# fpga register map
File version: 1.0
Registers are 32-bit, read-write, reset 0x0 unless marked. A register's access mark holds for its fields unless they carry their own. Offsets are from the block's base; [hi:lo] are bit positions; {n}, {i} and the like mark numbered series; 'fields as' and 'values as' point back to an identical list; <NAME> marks a mode.

## steppers — 8-channel stepper motor step/dir pulse generator (2 banks of 4)
Base 0x90000D00
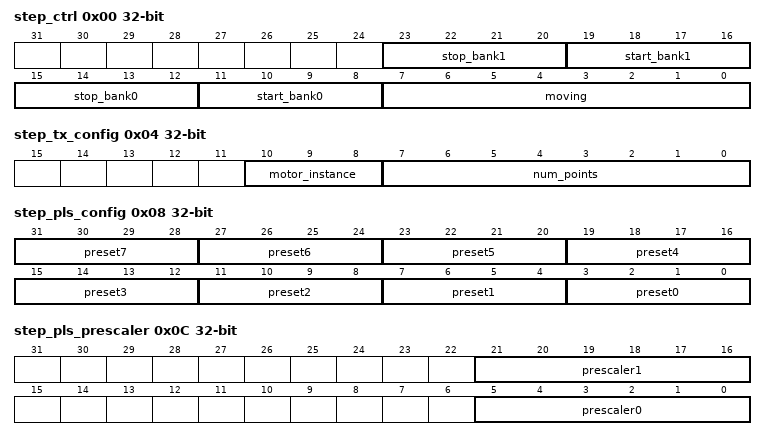
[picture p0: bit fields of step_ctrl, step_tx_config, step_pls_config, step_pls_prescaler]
0x00 step_ctrl — start/stop control - WRITE: start/stop strobes per motor (bank 0 = motors 0-3, bank 1 = motors 4-7); READ: per-motor moving status
  [23:20] stop_bank1 wo — stop strobe, bit N = motor (N+4) (bank 1, motors 4-7) - write-only, always reads as 0
  [19:16] start_bank1 wo — start strobe, bit N = motor (N+4) (bank 1, motors 4-7) - write-only, always reads as 0
  [15:12] stop_bank0 wo — stop strobe, bit N = motor N (bank 0, motors 0-3) - write-only, always reads as 0
  [11:8] start_bank0 wo — start strobe, bit N = motor N (bank 0, motors 0-3) - write-only, always reads as 0
  [7:0] moving ro — per-motor moving status (bit N = motor N is moving) - read-only, ignored on write
0x04 step_tx_config — segment table streaming configuration - selects which motor subsequent step_seg_ctst/step_seg_spdm writes and reads target, and rewinds both the write and read pointers to segment 0
  [10:8] motor_instance — which motor (0-7) subsequent step_seg_ctst/step_seg_spdm accesses target
  [7:0] num_points — number of segments about to be streamed (informational - clamped internally to the segment table's actual capacity)
0x08 step_pls_config — per-motor step pulse width preset (tick count - 1). Combined with that motor's bank prescaler in step_pls_prescaler: pulse width = (prescaler+1) * (preset+1) sys_clk cycles
  [4n+3:4n] preset{n} (n=0..7) — motor {n} pulse-width preset (tick count - 1)
0x0C step_pls_prescaler — per-bank step pulse width prescaler (sys_clk cycles per tick - 1). Bank 0 = motors 0-3 (low 16-bit half, bits[5:0]), bank 1 = motors 4-7 (high 16-bit half, bits[21:16]) - split this way so either field can widen, or other per-bank config bits can be added, without touching the other bank's half
  [21:16] prescaler1 — bank 1 (motors 4-7) prescaler (sys_clk cycles per tick - 1), high 16-bit half
  [5:0] prescaler0 — bank 0 (motors 0-3) prescaler (sys_clk cycles per tick - 1), low 16-bit half
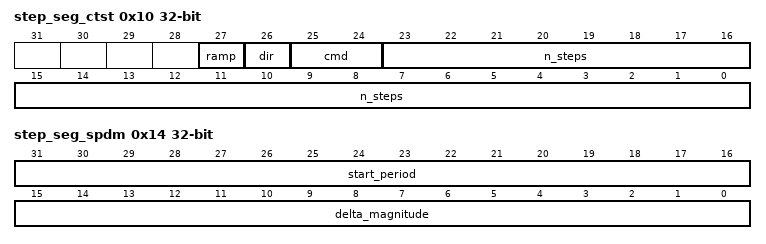
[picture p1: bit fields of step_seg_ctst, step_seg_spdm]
0x10 step_seg_ctst — segment table CTST word - command/direction/step-count for the segment addressed by step_tx_config's motor_instance and the current streaming pointer (advances on step_seg_spdm access, not this one)
  [27] ramp — whether this segment's period ramps up or down progresses
    0=UP (period decreases each step (accelerating)); 1=DOWN (period increases each step (decelerating))
  [26] dir — step direction for this segment
    0=NORMAL (forward/increasing position); 1=REVERSE (reverse/decreasing position)
  [25:24] cmd — segment command
    1=MOVE (move this segment then seamlessly continue into the next segment); 2=MOVE_HALT (move this segment then halt, requiring a fresh start strobe); 3=MOVE_HALT_WAIT (move this segment then halt, requiring a fresh start strobe (reserved alias of MOVE_HALT))
  [23:0] n_steps — number of steps in this segment
0x14 step_seg_spdm — segment table SPDM word - start period/delta magnitude for the segment addressed by step_tx_config's motor_instance and the current streaming pointer (advances the streaming pointer on access - write or read)
  [31:16] start_period — starting period for this segment, in stepper ticks
  [15:0] delta_magnitude — per-step period change magnitude, in stepper ticks
{0x20+4i} step_status_{i} ro (i=0..7) — motor {i} status
  [0] moving — 1 = motor is currently moving
{0x40+4i} step_pos_{i} ro (i=0..7) — motor {i} current absolute position, in steps (signed, two's complement)
  [31:0] position — current absolute position (signed, two's complement)

## timer_pwm — 4 independent 8-bit timers (source clock, 8-bit prescaler, 8-bit auto-reload) feeding 12 flexibly-mapped PWM output channels (PM1-4, OT1-8)
Base 0x90000E00
0x00 pwm_ctrl — master PWM output control - disabling forces every one of the 12 PWM pins LOW regardless of per-channel enable/polarity, and drives ot_en to its inactive (isolated) level
  [0] output_enable — 1 = PWM outputs active and ot_en drives OT1-8's isolation buffer enabled; 0 (reset default) = every PWM pin forced LOW and OT1-8 electrically isolated
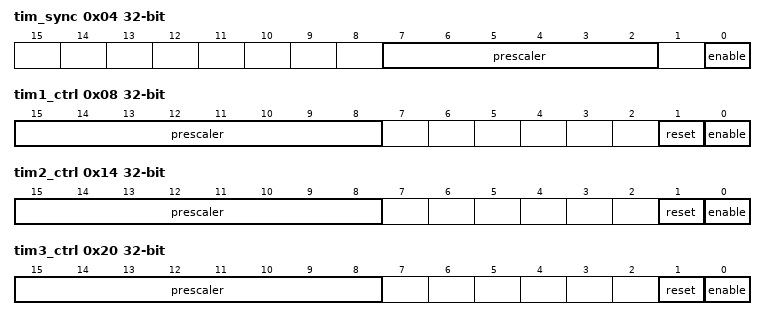
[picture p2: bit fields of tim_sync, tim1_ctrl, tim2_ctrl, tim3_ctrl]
0x04 tim_sync — global timer counting gate - lets every configured timer be started phase-aligned on the same sys_clk edge, plus a shared prescaler ahead of all 4 timers' own prescalers
  [7:2] prescaler — divide-1, shared by all 4 timers ahead of each timer's own timN_ctrl.prescaler: a timer only advances on a sys_clk cycle this shared stage ticks on, so the effective divide to one timer tick is (prescaler+1) * (timN_ctrl.prescaler+1) sys_clk cycles. Parked at this value (not counting) whenever enable=0, so every timer's phase relative to it is deterministic the instant sync starts
  [0] enable — 1 = every timer with its own timN_ctrl.enable set counts; 0 (reset default) = no timer counts, regardless of its own enable bit
0x08 tim1_ctrl — timer 1 control
  [15:8] prescaler — divide-1: the counter advances one tick every (prescaler+1) sys_clk cycles
  [1] reset — write 1 to reset this timer's counter to 0. self-clearing, always reads back 0
  [0] enable — 1 = this timer counts (subject to tim_sync.enable)
{0x0+0xC*i} tim{i}_arr (i=1..4) — timer {i} auto-reload value - the counter wraps to 0 the tick after reaching this value
  [7:0] value — auto-reload value
{0x4+0xC*i} tim{i}_cnt (i=1..4) — timer {i} current counter value - also host-writable, to set an initial counter value before starting via tim_sync
  [7:0] value — current counter value
0x14 tim2_ctrl — timer 2 control
  fields as tim1_ctrl
0x20 tim3_ctrl — timer 3 control
  fields as tim1_ctrl
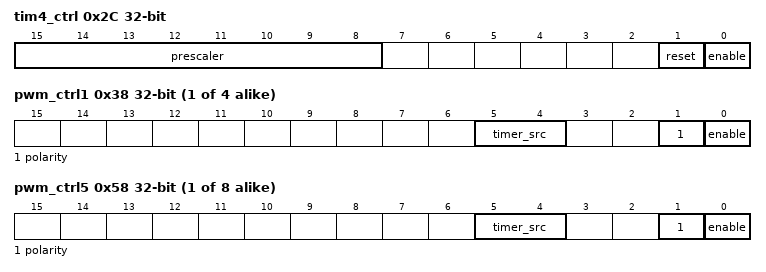
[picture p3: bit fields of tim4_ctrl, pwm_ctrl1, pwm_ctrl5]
0x2C tim4_ctrl — timer 4 control
  fields as tim1_ctrl
{0x30+8i} pwm_ctrl{i} (i=1..4) — PWM channel {i} (PM{i}) control
  [5:4] timer_src — which of the 4 timers this channel compares against
    {v}=TIM{v+1} (compare against timer {v+1}'s counter) (v=0..3)
  [1] polarity — 1 (inverted) = pin LOW while counter < compare, HIGH once counter >= compare; 0 (normal) = pin HIGH while counter < compare, LOW once counter >= compare. Either way the active phase is the first `compare` ticks of the period, and the pin returns to that active level the instant the timer's counter resets to 0 (auto-reload wrap or an explicit timN_ctrl.reset)
  [0] enable — 1 = this channel drives its pin from its selected timer's comparator; 0 (reset default) = pin forced LOW regardless of polarity
{0x34+8i} pwm_cmp{i} (i=1..4) — PWM channel {i} (PM{i}) compare value
  [7:0] value — 8-bit compare value, compared against the selected timer's counter
{0x30+8i} pwm_ctrl{i} (i=5..12) — PWM channel {i} (OT{i-4}) control
  fields as pwm_ctrl1
{0x34+8i} pwm_cmp{i} (i=5..12) — PWM channel {i} (OT{i-4}) compare value
  fields as pwm_cmp1

## system1 — system block 1
Base 0x9000FF00
0xFC marker ro reset 0xDEADC0DE — fixed marker value
  [31:0] marker — fixed marker
